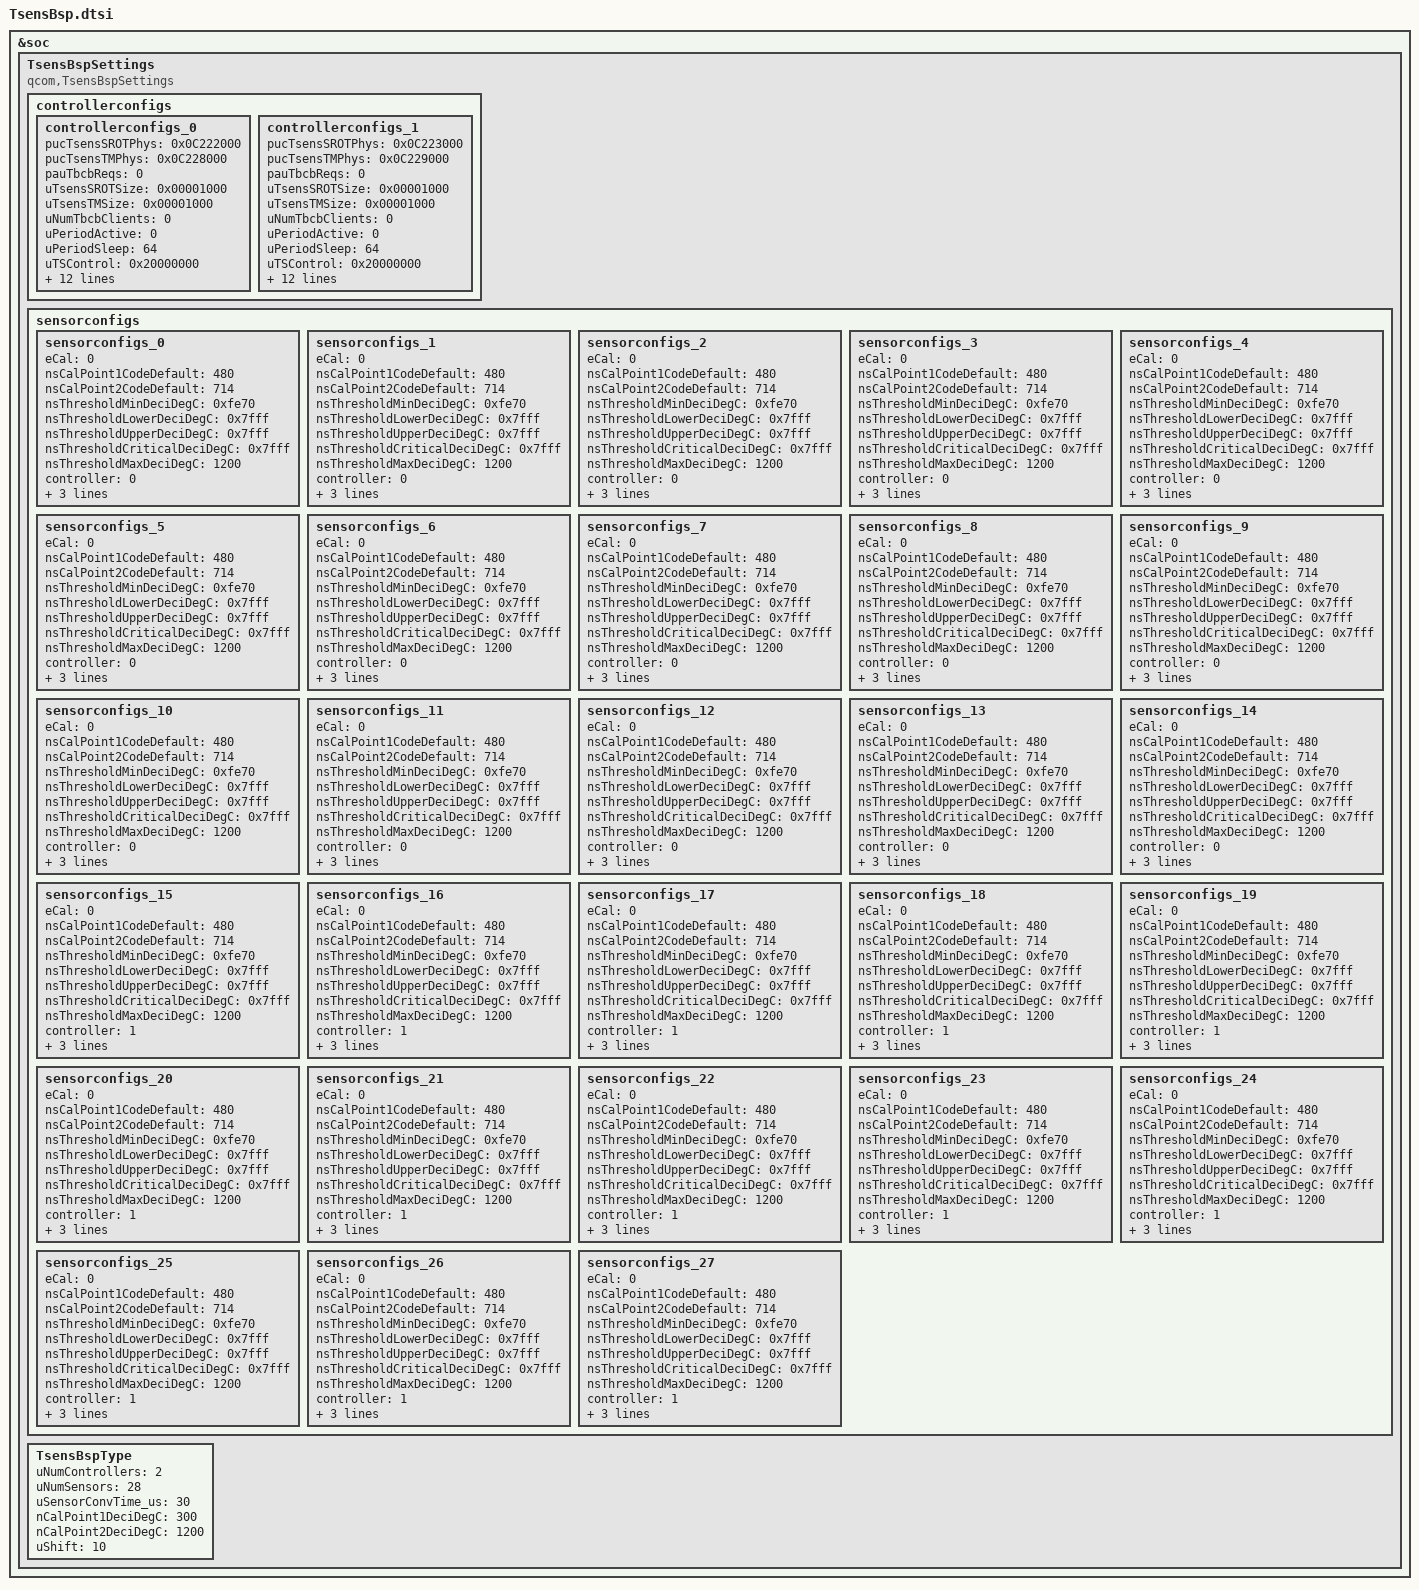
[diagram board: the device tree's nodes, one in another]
&soc {
	TsensBspSettings{
		compatible = "qcom,TsensBspSettings";
		controllerconfigs{
			controllerconfigs_0{
				pucTsensSROTPhys      = /bits/ 64 <0x0C222000>;
				pucTsensTMPhys        = /bits/ 64 <0x0C228000>;
				pauTbcbReqs           = /bits/ 64 <0>;
				uTsensSROTSize        = <0x00001000>;
				uTsensTMSize          = <0x00001000>;
				uNumTbcbClients       = <0>;
				uPeriodActive         = <0>;
				uPeriodSleep          = <64>;
				uTSControl            = <0x20000000>;
				uTSConfig             = <0x0>;
				uSidebandEnMask       = <0x7fff>;
				uWatchdogLoadVal      = <9850>;
				uZeroCEnMask          = <0x7fff>;
				nsZeroCSetDeciDegC    = /bits/ 16 <50>;
				nsZeroCResetDeciDegC  = /bits/ 16 <100>;
				bPSHoldResetEn        = /bits/ 8 <1>;
				bAutoAdjustPeriod     = /bits/ 8 <1>;
				bStandAlone           = /bits/ 8 <0>;
				bPWMEn                = /bits/ 8 <0>;
				bWatchdogEn           = /bits/ 8 <1>;
				bWatchdogResetEn      = /bits/ 8 <1>;
			};
			controllerconfigs_1{
				pucTsensSROTPhys      = /bits/ 64 <0x0C223000>;
				pucTsensTMPhys        = /bits/ 64 <0x0C229000>;
				pauTbcbReqs           = /bits/ 64 <0>;
				uTsensSROTSize        = <0x00001000>;
				uTsensTMSize          = <0x00001000>;
				uNumTbcbClients       = <0>;
				uPeriodActive         = <0>;
				uPeriodSleep          = <64>;
				uTSControl            = <0x20000000>;
				uTSConfig             = <0x0>;
				uSidebandEnMask       = <0x3fbf>;
				uWatchdogLoadVal      = <9850>;
				uZeroCEnMask          = <0x3fbf>;
				nsZeroCSetDeciDegC    = /bits/ 16 <50>;
				nsZeroCResetDeciDegC  = /bits/ 16 <100>;
				bPSHoldResetEn        = /bits/ 8 <1>;
				bAutoAdjustPeriod     = /bits/ 8 <1>;
				bStandAlone           = /bits/ 8 <0>;
				bPWMEn                = /bits/ 8 <0>;
				bWatchdogEn           = /bits/ 8 <1>;
				bWatchdogResetEn      = /bits/ 8 <1>;
			};
		};
		sensorconfigs{
			sensorconfigs_0{
				eCal                        = <0>;
				nsCalPoint1CodeDefault      = /bits/ 16 <480>;
				nsCalPoint2CodeDefault      = /bits/ 16 <714>;
				nsThresholdMinDeciDegC      = /bits/ 16 <0xfe70>;
				nsThresholdLowerDeciDegC    = /bits/ 16 <0x7fff>;
				nsThresholdUpperDeciDegC    = /bits/ 16 <0x7fff>;
				nsThresholdCriticalDeciDegC = /bits/ 16 <0x7fff>;
				nsThresholdMaxDeciDegC      = /bits/ 16 <1200>;
				controller                  = /bits/ 8 <0>;
				ucChannel                   = /bits/ 8 <0>;
				ucSensorID                  = /bits/ 8 <0>;
				ucFuseIdx                   = /bits/ 8 <0>;
			};
			sensorconfigs_1{
				eCal                        = <0>;
				nsCalPoint1CodeDefault      = /bits/ 16 <480>;
				nsCalPoint2CodeDefault      = /bits/ 16 <714>;
				nsThresholdMinDeciDegC      = /bits/ 16 <0xfe70>;
				nsThresholdLowerDeciDegC    = /bits/ 16 <0x7fff>;
				nsThresholdUpperDeciDegC    = /bits/ 16 <0x7fff>;
				nsThresholdCriticalDeciDegC = /bits/ 16 <0x7fff>;
				nsThresholdMaxDeciDegC      = /bits/ 16 <1200>;
				controller                  = /bits/ 8 <0>;
				ucChannel                   = /bits/ 8 <1>;
				ucSensorID                  = /bits/ 8 <1>;
				ucFuseIdx                   = /bits/ 8 <1>;
			};
			sensorconfigs_2{
				eCal                        = <0>;
				nsCalPoint1CodeDefault      = /bits/ 16 <480>;
				nsCalPoint2CodeDefault      = /bits/ 16 <714>;
				nsThresholdMinDeciDegC      = /bits/ 16 <0xfe70>;
				nsThresholdLowerDeciDegC    = /bits/ 16 <0x7fff>;
				nsThresholdUpperDeciDegC    = /bits/ 16 <0x7fff>;
				nsThresholdCriticalDeciDegC = /bits/ 16 <0x7fff>;
				nsThresholdMaxDeciDegC      = /bits/ 16 <1200>;
				controller                  = /bits/ 8 <0>;
				ucChannel                   = /bits/ 8 <2>;
				ucSensorID                  = /bits/ 8 <2>;
				ucFuseIdx                   = /bits/ 8 <2>;
			};
			sensorconfigs_3{
				eCal                        = <0>;
				nsCalPoint1CodeDefault      = /bits/ 16 <480>;
				nsCalPoint2CodeDefault      = /bits/ 16 <714>;
				nsThresholdMinDeciDegC      = /bits/ 16 <0xfe70>;
				nsThresholdLowerDeciDegC    = /bits/ 16 <0x7fff>;
				nsThresholdUpperDeciDegC    = /bits/ 16 <0x7fff>;
				nsThresholdCriticalDeciDegC = /bits/ 16 <0x7fff>;
				nsThresholdMaxDeciDegC      = /bits/ 16 <1200>;
				controller                  = /bits/ 8 <0>;
				ucChannel                   = /bits/ 8 <3>;
				ucSensorID                  = /bits/ 8 <3>;
				ucFuseIdx                   = /bits/ 8 <3>;
			};
			sensorconfigs_4{
				eCal                        = <0>;
				nsCalPoint1CodeDefault      = /bits/ 16 <480>;
				nsCalPoint2CodeDefault      = /bits/ 16 <714>;
				nsThresholdMinDeciDegC      = /bits/ 16 <0xfe70>;
				nsThresholdLowerDeciDegC    = /bits/ 16 <0x7fff>;
				nsThresholdUpperDeciDegC    = /bits/ 16 <0x7fff>;
				nsThresholdCriticalDeciDegC = /bits/ 16 <0x7fff>;
				nsThresholdMaxDeciDegC      = /bits/ 16 <1200>;
				controller                  = /bits/ 8 <0>;
				ucChannel                   = /bits/ 8 <4>;
				ucSensorID                  = /bits/ 8 <4>;
				ucFuseIdx                   = /bits/ 8 <4>;
			};
			sensorconfigs_5{
				eCal                        = <0>;
				nsCalPoint1CodeDefault      = /bits/ 16 <480>;
				nsCalPoint2CodeDefault      = /bits/ 16 <714>;
				nsThresholdMinDeciDegC      = /bits/ 16 <0xfe70>;
				nsThresholdLowerDeciDegC    = /bits/ 16 <0x7fff>;
				nsThresholdUpperDeciDegC    = /bits/ 16 <0x7fff>;
				nsThresholdCriticalDeciDegC = /bits/ 16 <0x7fff>;
				nsThresholdMaxDeciDegC      = /bits/ 16 <1200>;
				controller                  = /bits/ 8 <0>;
				ucChannel                   = /bits/ 8 <5>;
				ucSensorID                  = /bits/ 8 <5>;
				ucFuseIdx                   = /bits/ 8 <5>;
			};
			sensorconfigs_6{
				eCal                        = <0>;
				nsCalPoint1CodeDefault      = /bits/ 16 <480>;
				nsCalPoint2CodeDefault      = /bits/ 16 <714>;
				nsThresholdMinDeciDegC      = /bits/ 16 <0xfe70>;
				nsThresholdLowerDeciDegC    = /bits/ 16 <0x7fff>;
				nsThresholdUpperDeciDegC    = /bits/ 16 <0x7fff>;
				nsThresholdCriticalDeciDegC = /bits/ 16 <0x7fff>;
				nsThresholdMaxDeciDegC      = /bits/ 16 <1200>;
				controller                  = /bits/ 8 <0>;
				ucChannel                   = /bits/ 8 <6>;
				ucSensorID                  = /bits/ 8 <6>;
				ucFuseIdx                   = /bits/ 8 <6>;
			};
			sensorconfigs_7{
				eCal                        = <0>;
				nsCalPoint1CodeDefault      = /bits/ 16 <480>;
				nsCalPoint2CodeDefault      = /bits/ 16 <714>;
				nsThresholdMinDeciDegC      = /bits/ 16 <0xfe70>;
				nsThresholdLowerDeciDegC    = /bits/ 16 <0x7fff>;
				nsThresholdUpperDeciDegC    = /bits/ 16 <0x7fff>;
				nsThresholdCriticalDeciDegC = /bits/ 16 <0x7fff>;
				nsThresholdMaxDeciDegC      = /bits/ 16 <1200>;
				controller                  = /bits/ 8 <0>;
				ucChannel                   = /bits/ 8 <7>;
				ucSensorID                  = /bits/ 8 <7>;
				ucFuseIdx                   = /bits/ 8 <7>;
			};
			sensorconfigs_8{
				eCal                        = <0>;
				nsCalPoint1CodeDefault      = /bits/ 16 <480>;
				nsCalPoint2CodeDefault      = /bits/ 16 <714>;
				nsThresholdMinDeciDegC      = /bits/ 16 <0xfe70>;
				nsThresholdLowerDeciDegC    = /bits/ 16 <0x7fff>;
				nsThresholdUpperDeciDegC    = /bits/ 16 <0x7fff>;
				nsThresholdCriticalDeciDegC = /bits/ 16 <0x7fff>;
				nsThresholdMaxDeciDegC      = /bits/ 16 <1200>;
				controller                  = /bits/ 8 <0>;
				ucChannel                   = /bits/ 8 <8>;
				ucSensorID                  = /bits/ 8 <8>;
				ucFuseIdx                   = /bits/ 8 <8>;
			};
			sensorconfigs_9{
				eCal                        = <0>;
				nsCalPoint1CodeDefault      = /bits/ 16 <480>;
				nsCalPoint2CodeDefault      = /bits/ 16 <714>;
				nsThresholdMinDeciDegC      = /bits/ 16 <0xfe70>;
				nsThresholdLowerDeciDegC    = /bits/ 16 <0x7fff>;
				nsThresholdUpperDeciDegC    = /bits/ 16 <0x7fff>;
				nsThresholdCriticalDeciDegC = /bits/ 16 <0x7fff>;
				nsThresholdMaxDeciDegC      = /bits/ 16 <1200>;
				controller                  = /bits/ 8 <0>;
				ucChannel                   = /bits/ 8 <9>;
				ucSensorID                  = /bits/ 8 <9>;
				ucFuseIdx                   = /bits/ 8 <9>;
			};
			sensorconfigs_10{
				eCal                        = <0>;
				nsCalPoint1CodeDefault      = /bits/ 16 <480>;
				nsCalPoint2CodeDefault      = /bits/ 16 <714>;
				nsThresholdMinDeciDegC      = /bits/ 16 <0xfe70>;
				nsThresholdLowerDeciDegC    = /bits/ 16 <0x7fff>;
				nsThresholdUpperDeciDegC    = /bits/ 16 <0x7fff>;
				nsThresholdCriticalDeciDegC = /bits/ 16 <0x7fff>;
				nsThresholdMaxDeciDegC      = /bits/ 16 <1200>;
				controller                  = /bits/ 8 <0>;
				ucChannel                   = /bits/ 8 <10>;
				ucSensorID                  = /bits/ 8 <10>;
				ucFuseIdx                   = /bits/ 8 <10>;
			};
			sensorconfigs_11{
				eCal                        = <0>;
				nsCalPoint1CodeDefault      = /bits/ 16 <480>;
				nsCalPoint2CodeDefault      = /bits/ 16 <714>;
				nsThresholdMinDeciDegC      = /bits/ 16 <0xfe70>;
				nsThresholdLowerDeciDegC    = /bits/ 16 <0x7fff>;
				nsThresholdUpperDeciDegC    = /bits/ 16 <0x7fff>;
				nsThresholdCriticalDeciDegC = /bits/ 16 <0x7fff>;
				nsThresholdMaxDeciDegC      = /bits/ 16 <1200>;
				controller                  = /bits/ 8 <0>;
				ucChannel                   = /bits/ 8 <11>;
				ucSensorID                  = /bits/ 8 <11>;
				ucFuseIdx                   = /bits/ 8 <11>;
			};
			sensorconfigs_12{
				eCal                        = <0>;
				nsCalPoint1CodeDefault      = /bits/ 16 <480>;
				nsCalPoint2CodeDefault      = /bits/ 16 <714>;
				nsThresholdMinDeciDegC      = /bits/ 16 <0xfe70>;
				nsThresholdLowerDeciDegC    = /bits/ 16 <0x7fff>;
				nsThresholdUpperDeciDegC    = /bits/ 16 <0x7fff>;
				nsThresholdCriticalDeciDegC = /bits/ 16 <0x7fff>;
				nsThresholdMaxDeciDegC      = /bits/ 16 <1200>;
				controller                  = /bits/ 8 <0>;
				ucChannel                   = /bits/ 8 <12>;
				ucSensorID                  = /bits/ 8 <12>;
				ucFuseIdx                   = /bits/ 8 <12>;
			};
			sensorconfigs_13{
				eCal                        = <0>;
				nsCalPoint1CodeDefault      = /bits/ 16 <480>;
				nsCalPoint2CodeDefault      = /bits/ 16 <714>;
				nsThresholdMinDeciDegC      = /bits/ 16 <0xfe70>;
				nsThresholdLowerDeciDegC    = /bits/ 16 <0x7fff>;
				nsThresholdUpperDeciDegC    = /bits/ 16 <0x7fff>;
				nsThresholdCriticalDeciDegC = /bits/ 16 <0x7fff>;
				nsThresholdMaxDeciDegC      = /bits/ 16 <1200>;
				controller                  = /bits/ 8 <0>;
				ucChannel                   = /bits/ 8 <13>;
				ucSensorID                  = /bits/ 8 <13>;
				ucFuseIdx                   = /bits/ 8 <13>;
			};
			sensorconfigs_14{
				eCal                        = <0>;
				nsCalPoint1CodeDefault      = /bits/ 16 <480>;
				nsCalPoint2CodeDefault      = /bits/ 16 <714>;
				nsThresholdMinDeciDegC      = /bits/ 16 <0xfe70>;
				nsThresholdLowerDeciDegC    = /bits/ 16 <0x7fff>;
				nsThresholdUpperDeciDegC    = /bits/ 16 <0x7fff>;
				nsThresholdCriticalDeciDegC = /bits/ 16 <0x7fff>;
				nsThresholdMaxDeciDegC      = /bits/ 16 <1200>;
				controller                  = /bits/ 8 <0>;
				ucChannel                   = /bits/ 8 <14>;
				ucSensorID                  = /bits/ 8 <14>;
				ucFuseIdx                   = /bits/ 8 <14>;
			};
			sensorconfigs_15{
				eCal                        = <0>;
				nsCalPoint1CodeDefault      = /bits/ 16 <480>;
				nsCalPoint2CodeDefault      = /bits/ 16 <714>;
				nsThresholdMinDeciDegC      = /bits/ 16 <0xfe70>;
				nsThresholdLowerDeciDegC    = /bits/ 16 <0x7fff>;
				nsThresholdUpperDeciDegC    = /bits/ 16 <0x7fff>;
				nsThresholdCriticalDeciDegC = /bits/ 16 <0x7fff>;
				nsThresholdMaxDeciDegC      = /bits/ 16 <1200>;
				controller                  = /bits/ 8 <1>;
				ucChannel                   = /bits/ 8 <0>;
				ucSensorID                  = /bits/ 8 <0>;
				ucFuseIdx                   = /bits/ 8 <15>;
			};
			sensorconfigs_16{
				eCal                        = <0>;
				nsCalPoint1CodeDefault      = /bits/ 16 <480>;
				nsCalPoint2CodeDefault      = /bits/ 16 <714>;
				nsThresholdMinDeciDegC      = /bits/ 16 <0xfe70>;
				nsThresholdLowerDeciDegC    = /bits/ 16 <0x7fff>;
				nsThresholdUpperDeciDegC    = /bits/ 16 <0x7fff>;
				nsThresholdCriticalDeciDegC = /bits/ 16 <0x7fff>;
				nsThresholdMaxDeciDegC      = /bits/ 16 <1200>;
				controller                  = /bits/ 8 <1>;
				ucChannel                   = /bits/ 8 <1>;
				ucSensorID                  = /bits/ 8 <1>;
				ucFuseIdx                   = /bits/ 8 <16>;
			};
			sensorconfigs_17{
				eCal                        = <0>;
				nsCalPoint1CodeDefault      = /bits/ 16 <480>;
				nsCalPoint2CodeDefault      = /bits/ 16 <714>;
				nsThresholdMinDeciDegC      = /bits/ 16 <0xfe70>;
				nsThresholdLowerDeciDegC    = /bits/ 16 <0x7fff>;
				nsThresholdUpperDeciDegC    = /bits/ 16 <0x7fff>;
				nsThresholdCriticalDeciDegC = /bits/ 16 <0x7fff>;
				nsThresholdMaxDeciDegC      = /bits/ 16 <1200>;
				controller                  = /bits/ 8 <1>;
				ucChannel                   = /bits/ 8 <2>;
				ucSensorID                  = /bits/ 8 <2>;
				ucFuseIdx                   = /bits/ 8 <17>;
			};
			sensorconfigs_18{
				eCal                        = <0>;
				nsCalPoint1CodeDefault      = /bits/ 16 <480>;
				nsCalPoint2CodeDefault      = /bits/ 16 <714>;
				nsThresholdMinDeciDegC      = /bits/ 16 <0xfe70>;
				nsThresholdLowerDeciDegC    = /bits/ 16 <0x7fff>;
				nsThresholdUpperDeciDegC    = /bits/ 16 <0x7fff>;
				nsThresholdCriticalDeciDegC = /bits/ 16 <0x7fff>;
				nsThresholdMaxDeciDegC      = /bits/ 16 <1200>;
				controller                  = /bits/ 8 <1>;
				ucChannel                   = /bits/ 8 <3>;
				ucSensorID                  = /bits/ 8 <3>;
				ucFuseIdx                   = /bits/ 8 <18>;
			};
			sensorconfigs_19{
				eCal                        = <0>;
				nsCalPoint1CodeDefault      = /bits/ 16 <480>;
				nsCalPoint2CodeDefault      = /bits/ 16 <714>;
				nsThresholdMinDeciDegC      = /bits/ 16 <0xfe70>;
				nsThresholdLowerDeciDegC    = /bits/ 16 <0x7fff>;
				nsThresholdUpperDeciDegC    = /bits/ 16 <0x7fff>;
				nsThresholdCriticalDeciDegC = /bits/ 16 <0x7fff>;
				nsThresholdMaxDeciDegC      = /bits/ 16 <1200>;
				controller                  = /bits/ 8 <1>;
				ucChannel                   = /bits/ 8 <4>;
				ucSensorID                  = /bits/ 8 <4>;
				ucFuseIdx                   = /bits/ 8 <19>;
			};
			sensorconfigs_20{
				eCal                        = <0>;
				nsCalPoint1CodeDefault      = /bits/ 16 <480>;
				nsCalPoint2CodeDefault      = /bits/ 16 <714>;
				nsThresholdMinDeciDegC      = /bits/ 16 <0xfe70>;
				nsThresholdLowerDeciDegC    = /bits/ 16 <0x7fff>;
				nsThresholdUpperDeciDegC    = /bits/ 16 <0x7fff>;
				nsThresholdCriticalDeciDegC = /bits/ 16 <0x7fff>;
				nsThresholdMaxDeciDegC      = /bits/ 16 <1200>;
				controller                  = /bits/ 8 <1>;
				ucChannel                   = /bits/ 8 <5>;
				ucSensorID                  = /bits/ 8 <5>;
				ucFuseIdx                   = /bits/ 8 <20>;
			};
			sensorconfigs_21{
				eCal                        = <0>;
				nsCalPoint1CodeDefault      = /bits/ 16 <480>;
				nsCalPoint2CodeDefault      = /bits/ 16 <714>;
				nsThresholdMinDeciDegC      = /bits/ 16 <0xfe70>;
				nsThresholdLowerDeciDegC    = /bits/ 16 <0x7fff>;
				nsThresholdUpperDeciDegC    = /bits/ 16 <0x7fff>;
				nsThresholdCriticalDeciDegC = /bits/ 16 <0x7fff>;
				nsThresholdMaxDeciDegC      = /bits/ 16 <1200>;
				controller                  = /bits/ 8 <1>;
				ucChannel                   = /bits/ 8 <7>;
				ucSensorID                  = /bits/ 8 <7>;
				ucFuseIdx                   = /bits/ 8 <21>;
			};
			sensorconfigs_22{
				eCal                        = <0>;
				nsCalPoint1CodeDefault      = /bits/ 16 <480>;
				nsCalPoint2CodeDefault      = /bits/ 16 <714>;
				nsThresholdMinDeciDegC      = /bits/ 16 <0xfe70>;
				nsThresholdLowerDeciDegC    = /bits/ 16 <0x7fff>;
				nsThresholdUpperDeciDegC    = /bits/ 16 <0x7fff>;
				nsThresholdCriticalDeciDegC = /bits/ 16 <0x7fff>;
				nsThresholdMaxDeciDegC      = /bits/ 16 <1200>;
				controller                  = /bits/ 8 <1>;
				ucChannel                   = /bits/ 8 <8>;
				ucSensorID                  = /bits/ 8 <8>;
				ucFuseIdx                   = /bits/ 8 <22>;
			};
			sensorconfigs_23{
				eCal                        = <0>;
				nsCalPoint1CodeDefault      = /bits/ 16 <480>;
				nsCalPoint2CodeDefault      = /bits/ 16 <714>;
				nsThresholdMinDeciDegC      = /bits/ 16 <0xfe70>;
				nsThresholdLowerDeciDegC    = /bits/ 16 <0x7fff>;
				nsThresholdUpperDeciDegC    = /bits/ 16 <0x7fff>;
				nsThresholdCriticalDeciDegC = /bits/ 16 <0x7fff>;
				nsThresholdMaxDeciDegC      = /bits/ 16 <1200>;
				controller                  = /bits/ 8 <1>;
				ucChannel                   = /bits/ 8 <9>;
				ucSensorID                  = /bits/ 8 <9>;
				ucFuseIdx                   = /bits/ 8 <23>;
			};
			sensorconfigs_24{
				eCal                        = <0>;
				nsCalPoint1CodeDefault      = /bits/ 16 <480>;
				nsCalPoint2CodeDefault      = /bits/ 16 <714>;
				nsThresholdMinDeciDegC      = /bits/ 16 <0xfe70>;
				nsThresholdLowerDeciDegC    = /bits/ 16 <0x7fff>;
				nsThresholdUpperDeciDegC    = /bits/ 16 <0x7fff>;
				nsThresholdCriticalDeciDegC = /bits/ 16 <0x7fff>;
				nsThresholdMaxDeciDegC      = /bits/ 16 <1200>;
				controller                  = /bits/ 8 <1>;
				ucChannel                   = /bits/ 8 <10>;
				ucSensorID                  = /bits/ 8 <10>;
				ucFuseIdx                   = /bits/ 8 <24>;
			};
			sensorconfigs_25{
				eCal                        = <0>;
				nsCalPoint1CodeDefault      = /bits/ 16 <480>;
				nsCalPoint2CodeDefault      = /bits/ 16 <714>;
				nsThresholdMinDeciDegC      = /bits/ 16 <0xfe70>;
				nsThresholdLowerDeciDegC    = /bits/ 16 <0x7fff>;
				nsThresholdUpperDeciDegC    = /bits/ 16 <0x7fff>;
				nsThresholdCriticalDeciDegC = /bits/ 16 <0x7fff>;
				nsThresholdMaxDeciDegC      = /bits/ 16 <1200>;
				controller                  = /bits/ 8 <1>;
				ucChannel                   = /bits/ 8 <11>;
				ucSensorID                  = /bits/ 8 <11>;
				ucFuseIdx                   = /bits/ 8 <25>;
			};
			sensorconfigs_26{
				eCal                        = <0>;
				nsCalPoint1CodeDefault      = /bits/ 16 <480>;
				nsCalPoint2CodeDefault      = /bits/ 16 <714>;
				nsThresholdMinDeciDegC      = /bits/ 16 <0xfe70>;
				nsThresholdLowerDeciDegC    = /bits/ 16 <0x7fff>;
				nsThresholdUpperDeciDegC    = /bits/ 16 <0x7fff>;
				nsThresholdCriticalDeciDegC = /bits/ 16 <0x7fff>;
				nsThresholdMaxDeciDegC      = /bits/ 16 <1200>;
				controller                  = /bits/ 8 <1>;
				ucChannel                   = /bits/ 8 <12>;
				ucSensorID                  = /bits/ 8 <12>;
				ucFuseIdx                   = /bits/ 8 <26>;
			};
			sensorconfigs_27{
				eCal                        = <0>;
				nsCalPoint1CodeDefault      = /bits/ 16 <480>;
				nsCalPoint2CodeDefault      = /bits/ 16 <714>;
				nsThresholdMinDeciDegC      = /bits/ 16 <0xfe70>;
				nsThresholdLowerDeciDegC    = /bits/ 16 <0x7fff>;
				nsThresholdUpperDeciDegC    = /bits/ 16 <0x7fff>;
				nsThresholdCriticalDeciDegC = /bits/ 16 <0x7fff>;
				nsThresholdMaxDeciDegC      = /bits/ 16 <1200>;
				controller                  = /bits/ 8 <1>;
				ucChannel                   = /bits/ 8 <13>;
				ucSensorID                  = /bits/ 8 <13>;
				ucFuseIdx                   = /bits/ 8 <27>;
			};
		};
		TsensBspType{
			uNumControllers     = <2>;
			uNumSensors         = <28>;
			uSensorConvTime_us  = <30>;
			nCalPoint1DeciDegC  = <300>;
			nCalPoint2DeciDegC  = <1200>;
			uShift              = <10>;
		};
	};

};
